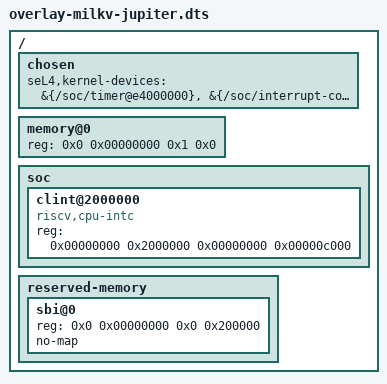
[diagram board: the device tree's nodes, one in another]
/*
 * Copyright 2025, UNSW
 *
 * SPDX-License-Identifier: GPL-2.0-only
 */

/ {
    chosen {
        seL4,kernel-devices =
            &{/soc/timer@e4000000},
            &{/soc/interrupt-controller@e0000000};
    };

    /* 4GiB of main memory */
    memory@0 {
        device_type = "memory";
        reg = <0x0 0x00000000 0x1 0x0>;
    };

    soc {
        clint@2000000 {
            compatible = "riscv,cpu-intc";
            reg = <0x00000000 0x2000000 0x00000000 0x00000c000>;
        };
    };

    /* Reserve 2 MiB for SBI at the start of RAM (0x40000000 - 0x40200000). This
     * is exactly one "megapage" in the MMU table. It leaves plenty of space for
     * further SBI experimenting, given the known usage (as of June 2021) is:
     * - BBL: 76 KiB (= 0x13000)
     * - OpenSBI: 128 KiB (= 0x20000) with PMP protection
     */
    reserved-memory {
        #address-cells = <0x02>;
        #size-cells = <0x02>;
        ranges;
        sbi@0 {
            reg = <0x0 0x00000000 0x0 0x200000>;
            no-map;
        };
    };
};
